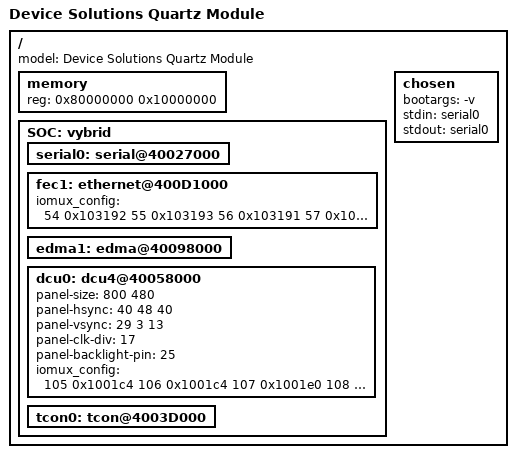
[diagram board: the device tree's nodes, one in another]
/*-
 * Copyright (c) 2014 Ruslan Bukin <br@bsdpad.com>
 * All rights reserved.
 *
 * Redistribution and use in source and binary forms, with or without
 * modification, are permitted provided that the following conditions
 * are met:
 * 1. Redistributions of source code must retain the above copyright
 *    notice, this list of conditions and the following disclaimer.
 * 2. Redistributions in binary form must reproduce the above copyright
 *    notice, this list of conditions and the following disclaimer in the
 *    documentation and/or other materials provided with the distribution.
 *
 * THIS SOFTWARE IS PROVIDED BY THE AUTHOR AND CONTRIBUTORS ``AS IS'' AND
 * ANY EXPRESS OR IMPLIED WARRANTIES, INCLUDING, BUT NOT LIMITED TO, THE
 * IMPLIED WARRANTIES OF MERCHANTABILITY AND FITNESS FOR A PARTICULAR PURPOSE
 * ARE DISCLAIMED. IN NO EVENT SHALL THE AUTHOR OR CONTRIBUTORS BE LIABLE
 * FOR ANY DIRECT, INDIRECT, INCIDENTAL, SPECIAL, EXEMPLARY, OR CONSEQUENTIAL
 * DAMAGES (INCLUDING, BUT NOT LIMITED TO, PROCUREMENT OF SUBSTITUTE GOODS
 * OR SERVICES; LOSS OF USE, DATA, OR PROFITS; OR BUSINESS INTERRUPTION)
 * HOWEVER CAUSED AND ON ANY THEORY OF LIABILITY, WHETHER IN CONTRACT, STRICT
 * LIABILITY, OR TORT (INCLUDING NEGLIGENCE OR OTHERWISE) ARISING IN ANY WAY
 * OUT OF THE USE OF THIS SOFTWARE, EVEN IF ADVISED OF THE POSSIBILITY OF
 * SUCH DAMAGE.
 *
 * $FreeBSD$
 */

/dts-v1/;

/include/ "vybrid.dtsi"

/ {
	model = "Device Solutions Quartz Module";

	memory {
		device_type = "memory";
		reg = < 0x80000000 0x10000000 >;	/* 256MB RAM */
	};

	SOC: vybrid {
		serial0: serial@40027000 {
			status = "okay";
		};

		fec1: ethernet@400D1000 {
			status = "okay";
			iomux_config = < 54 0x103192
					 55 0x103193
					 56 0x103191
					 57 0x103191
					 58 0x103191
					 59 0x103191
					 60 0x103192
					 61 0x103192
					 62 0x103192
					  0 0x203191 >;
		};

		edma1: edma@40098000 {
			status = "okay";
		};

		dcu0: dcu4@40058000 {
			status = "okay";

			panel-size = < 800 480 >;
			panel-hsync = < 40 48 40 >;
			panel-vsync = < 29 3 13 >;
			panel-clk-div = < 17 >;
			panel-backlight-pin = < 25 >;

			iomux_config = < 105 0x1001c4 /* hsync */
					 106 0x1001c4 /* vsync */
					 107 0x1001e0 /* pclk */
					 108 0x1001e0
					 109 0x1001be /* de */
					 110 0x1001e0 /* r0 */
					 111 0x1001e0
					 112 0x1001e0
					 113 0x1001e0
					 114 0x1001e0
					 115 0x1001e0
					 116 0x1001e0
					 117 0x1001e0
					 118 0x1001e0 /* g0 */
					 119 0x1001e0
					 120 0x1001e0
					 121 0x1001e0
					 122 0x1001e0
					 123 0x1001e0
					 124 0x1001e0
					 125 0x1001e0
					 126 0x1001e0 /* b0 */
					 127 0x1001e0
					 128 0x1001e0
					 129 0x1001e0
					 130 0x1001e0
					 131 0x1001e0
					 132 0x1001e0
					 133 0x1001e0
					  25 0x0001be >; /* led */
		};

		tcon0: tcon@4003D000 {
			status = "okay";
		};
	};

	chosen {
		bootargs = "-v";
		stdin = "serial0";
		stdout = "serial0";
	};
};
